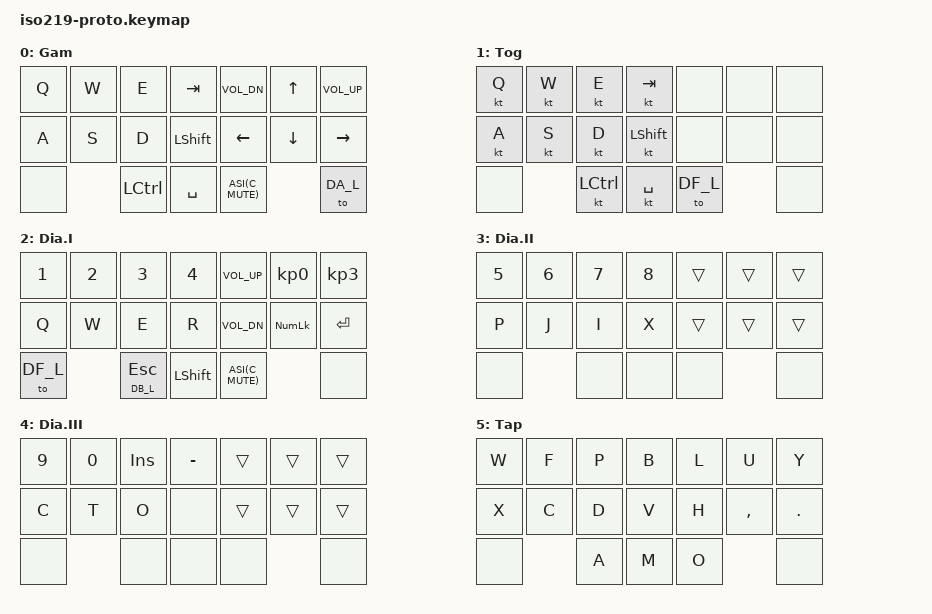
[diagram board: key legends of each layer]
/*
 * Copyright (c) 2024 Rooks
 *
 * SPDX-License-Identifier: MIT
 */

#include <behaviors.dtsi>
#include <dt-bindings/zmk/keys.h>
#include <dt-bindings/zmk/pointing.h>

// layer sticky (mo X sl X )
#define MOSL(layer) &gls layer layer
// Autoshift Macro and Inversion
#define AS(keycode)  &as LS(keycode) keycode
#define ASI(keycode) &as keycode LS(keycode)

#define DF_L 0
#define TG_L 1
#define DA_L 2
#define DB_L 3
#define DC_L 4
#define KP_L 5

/*
 *   0  1  2  3  4  5  6
 *   7  8  9 10 11 12 13
 *  14    15 16 17    18
 */

/ {
    behaviors {
        as: auto_shift {
            compatible = "zmk,behavior-hold-tap";
            #binding-cells = <2>;
            bindings = <&kp>, <&kp>;
            flavor = "tap-preferred";
            tapping-term-ms = <200>;
            quick-tap-ms = <100>;
        };
        ght: game_hold_tap {
            compatible = "zmk,behavior-hold-tap";
            #binding-cells = <2>;
            bindings = <&kp>, <&kp>;
            flavor = "hold-preferred";
            tapping-term-ms = <150>;
        };
        gls: game_layer_sticky {
            compatible = "zmk,behavior-hold-tap";
            #binding-cells = <2>;
            bindings = <&mo>, <&sl>;
            flavor = "hold-preferred";
            tapping-term-ms = <150>;
        };
        glt: game_layer_tap {
            compatible = "zmk,behavior-hold-tap";
            #binding-cells = <2>;
            bindings = <&mo>, <&kp>;
            flavor = "hold-preferred";
            tapping-term-ms = <150>;
        };
    };

    keymap {
        compatible = "zmk,keymap";

        default_layer {
            display-name = "Gam";
            bindings = <
                &kp Q &kp W &kp E    &kp TAB      &kp C_VOL_DN &kp UP   &kp C_VOL_UP
                &kp A &kp S &kp D    &kp LSHFT    &kp LEFT     &kp DOWN &kp RIGHT
                &none       &kp LCTL &kp SPACE    ASI(C_MUTE)           &to DA_L
            >;
        };

        toggles_layer {
            display-name = "Tog";
            bindings = <
                &kt Q &kt W &kt E    &kt TAB      &none &none &none
                &kt A &kt S &kt D    &kt LSHFT    &none &none &none
                &none       &kt LCTL &kt SPACE    &to DF_L    &none
            >;
        };

        diablo_layer {
            display-name = "Dia.I";
            bindings = <
                &kp N1   &kp N2 &kp N3 &kp N4       &kp C_VOL_UP &kp KP_N0  &kp KP_N3
                &kp Q    &kp W  &kp E  &kp R        &kp C_VOL_DN &kp KP_NUM &kp RET
                &to DF_L &glt DB_L ESC &kp LSHFT    ASI(C_MUTE)             &none
            >;
        };

        diablo_two_layer {
            display-name = "Dia.II";
            bindings = <
                &kp N5 &kp N6 &kp N7 &kp N8    &trans &trans &trans
                &kp P  &kp J  &kp I  &kp X     &trans &trans &trans
                &none         &none  &none     &none         &none
            >;
        };

        diablo_three_layer {
            display-name = "Dia.III";
            bindings = <
                &kp N9 &kp N0 &kp INS &kp MINUS    &trans &trans &trans
                &kp C  &kp T  &kp O   &none        &trans &trans &trans
                &none         &none   &none        &none         &none
            >;
        };

        tap_layer {
            display-name = "Tap";
            bindings = <
                &kp W &kp F &kp P &kp B    &kp L &kp U     &kp Y
                &kp X &kp C &kp D &kp V    &kp H &kp COMMA &kp DOT
                &none       &kp A &kp M    &kp O           &none
            >;
        };
    };

    combos {
        compatible = "zmk,combos";
        combo_boot       { timeout-ms = <50>; key-positions = <0 6 14 18>; bindings = <&bootloader>; };

//        combo_mute       { timeout-ms = <50>; key-positions = <6 7>;   bindings = <&kp C_MUTE>; layers = <NAV_L>;  };
//        combo_pp         { timeout-ms = <50>; key-positions = <8 9>;   bindings = <&kp C_PP>;   layers = <NAV_L>;  };

        combo_esc    { timeout-ms = <50>; key-positions = < 2 3 >; bindings = <&kp ESC>;    layers = <DF_L>; };
        combo_b      { timeout-ms = <50>; key-positions = < 0 2 >; bindings = <&kp B>;      layers = <DF_L>; };
        combo_g      { timeout-ms = <50>; key-positions = < 0 1 >; bindings = <&kp G>;      layers = <DF_L>; };
        combo_r      { timeout-ms = <50>; key-positions = < 1 2 >; bindings = <&kp R>;      layers = <DF_L>; };
        combo_f      { timeout-ms = <50>; key-positions = < 2 9 >; bindings = <&kp F>;      layers = <DF_L>; };
        combo_v      { timeout-ms = <50>; key-positions = < 1 9 >; bindings = <&kp V>;      layers = <DF_L>; };
        combo_z      { timeout-ms = <50>; key-positions = < 7 8 >; bindings = <&kp Z>;      layers = <DF_L>; };
        combo_x      { timeout-ms = <50>; key-positions = < 8 9 >; bindings = <&kp X>;      layers = <DF_L>; };
        combo_c      { timeout-ms = <50>; key-positions = < 9 15>; bindings = <&kp C>;      layers = <DF_L>; };
        combo_la     { timeout-ms = <50>; key-positions = <10 16>; bindings = <&kp LALT>;   layers = <DF_L>; };

        combo_ls_tg  { timeout-ms = <50>; key-positions = < 9 10>; bindings = <MOSL(TG_L)>; layers = <DF_L>; };

        combo_tg_b   { timeout-ms = <50>; key-positions = < 0 2 >; bindings = <&kt B>;      layers = <TG_L>; };
        combo_tg_g   { timeout-ms = <50>; key-positions = < 0 1 >; bindings = <&kt G>;      layers = <TG_L>; };
        combo_tg_r   { timeout-ms = <50>; key-positions = < 1 2 >; bindings = <&kt R>;      layers = <TG_L>; };
        combo_tg_f   { timeout-ms = <50>; key-positions = < 2 9 >; bindings = <&kt F>;      layers = <TG_L>; };
        combo_tg_v   { timeout-ms = <50>; key-positions = < 1 9 >; bindings = <&kt V>;      layers = <TG_L>; };
        combo_tg_z   { timeout-ms = <50>; key-positions = < 7 8 >; bindings = <&kt Z>;      layers = <TG_L>; };
        combo_tg_x   { timeout-ms = <50>; key-positions = < 8 9 >; bindings = <&kt X>;      layers = <TG_L>; };
        combo_tg_c   { timeout-ms = <50>; key-positions = < 9 15>; bindings = <&kt C>;      layers = <TG_L>; };
        combo_tg_la  { timeout-ms = <50>; key-positions = <10 16>; bindings = <&kt LALT>;   layers = <TG_L>; };

        combo_d2_lc  { timeout-ms = <50>; key-positions = < 9 15>; bindings = <&kp LCTRL>;  layers = <DA_L>; };
        combo_d2_grv { timeout-ms = <50>; key-positions = < 2 3 >; bindings = <&kp GRAVE>;  layers = <DA_L>; };
        combo_d2_3_z { timeout-ms = <50>; key-positions = <10 16>; bindings = <&glt DC_L Z>;layers = <DA_L>; };

        combo_ls_kp  { timeout-ms = <50>; key-positions = <11 17>; bindings = <MOSL(KP_L)>;                  };

        combo_kp_q   { timeout-ms = <50>; key-positions = < 0 1 >; bindings = <&kp Q>;      layers = <KP_L>; };
        combo_kp_z   { timeout-ms = <50>; key-positions = < 7 8 >; bindings = <&kp Z>;      layers = <KP_L>; };
        combo_kp_r   { timeout-ms = <50>; key-positions = < 0 7 >; bindings = <&kp R>;      layers = <KP_L>; };
        combo_kp_s   { timeout-ms = <50>; key-positions = < 1 8 >; bindings = <&kp S>;      layers = <KP_L>; };
        combo_kp_t   { timeout-ms = <50>; key-positions = < 2 9 >; bindings = <&kp T>;      layers = <KP_L>; };
        combo_kp_g   { timeout-ms = <50>; key-positions = < 3 10>; bindings = <&kp G>;      layers = <KP_L>; };
        combo_kp_j   { timeout-ms = <50>; key-positions = < 4 5 >; bindings = <&kp J>;      layers = <KP_L>; };
        combo_kp_k   { timeout-ms = <50>; key-positions = < 5 6 >; bindings = <&kp K>;      layers = <KP_L>; };
        combo_kp_n   { timeout-ms = <50>; key-positions = < 4 11>; bindings = <&kp N>;      layers = <KP_L>; };
        combo_kp_e   { timeout-ms = <50>; key-positions = < 5 12>; bindings = <&kp E>;      layers = <KP_L>; };
        combo_kp_i   { timeout-ms = <50>; key-positions = < 6 13>; bindings = <&kp I>;      layers = <KP_L>; };
        combo_kp_quo { timeout-ms = <50>; key-positions = <11 12>; bindings = <&kp QUOT>;   layers = <KP_L>; };
        combo_kp_slh { timeout-ms = <50>; key-positions = <12 13>; bindings = <&kp FSLH>;   layers = <KP_L>; };
    };

/*
 *   0  1  2  3      4  5  6
 *   7  8  9 10     11 12 13
 *  14    15 16     17    18
 */

};

// vim: ft=c
